# STM32F479 register map
File version: 2.0
CPU: CM4 r0p1, little endian, MPU, FPU, 4 interrupt priority bits
Registers are 32-bit, read-write, reset 0x0 unless marked. A register's access mark holds for its fields unless they carry their own. Offsets are from the block's base; [hi:lo] are bit positions; {n}, {i} and the like mark numbered series.

## HASH — Hash processor
Base 0x50060400
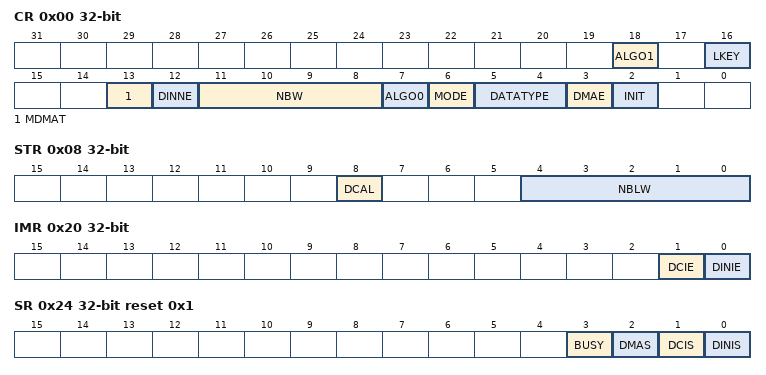
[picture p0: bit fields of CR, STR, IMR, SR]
0x00 CR access per field — control register
  [18] ALGO1 rw — ALGO
  [16] LKEY rw — Long key selection
  [13] MDMAT rw — Multiple DMA Transfers
  [12] DINNE ro — DIN not empty
  [11:8] NBW ro — Number of words already pushed
  [7] ALGO0 rw — Algorithm selection
  [6] MODE rw — Mode selection
  [5:4] DATATYPE rw — Data type selection
  [3] DMAE rw — DMA enable
  [2] INIT wo — Initialize message digest calculation
0x04 DIN — data input register
  [31:0] DATAIN — Data input
0x08 STR access per field — start register
  [8] DCAL wo — Digest calculation
  [4:0] NBLW rw — Number of valid bits in the last word of the message
{0xC+4i} HR{i} ro (i=0..4) — digest registers
  [31:0] H{i}
0x20 IMR — interrupt enable register
  [1] DCIE — Digest calculation completion interrupt enable
  [0] DINIE — Data input interrupt enable
0x24 SR access per field reset 0x1 — status register
  [3] BUSY ro — Busy bit
  [2] DMAS ro — DMA Status
  [1] DCIS rw — Digest calculation completion interrupt status
  [0] DINIS rw — Data input interrupt status
{0xF8+4i} CSR{i} (i=0..53) — context swap registers
0x310 HASH_HR0 ro — HASH digest register
  [31:0] H0
{0x310+4i} HASH_HR{i} ro (i=1..7) — read-only
  [31:0] H{i}

## I2C3 — Inter-integrated circuit
Base 0x40005C00
Same registers: I2C1 0x40005400, I2C2 0x40005800
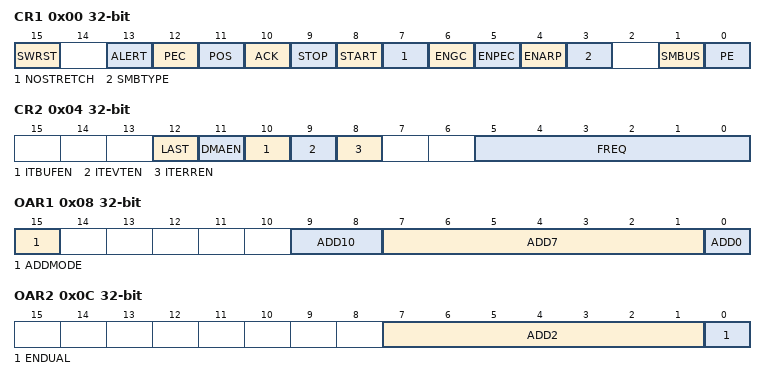
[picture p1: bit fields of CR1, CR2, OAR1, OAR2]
0x00 CR1 — Control register 1
  [15] SWRST — Software reset
  [13] ALERT — SMBus alert
  [12] PEC — Packet error checking
  [11] POS — Acknowledge/PEC Position (for data reception)
  [10] ACK — Acknowledge enable
  [9] STOP — Stop generation
  [8] START — Start generation
  [7] NOSTRETCH — Clock stretching disable (Slave mode)
  [6] ENGC — General call enable
  [5] ENPEC — PEC enable
  [4] ENARP — ARP enable
  [3] SMBTYPE — SMBus type
  [1] SMBUS — SMBus mode
  [0] PE — Peripheral enable
0x04 CR2 — Control register 2
  [12] LAST — DMA last transfer
  [11] DMAEN — DMA requests enable
  [10] ITBUFEN — Buffer interrupt enable
  [9] ITEVTEN — Event interrupt enable
  [8] ITERREN — Error interrupt enable
  [5:0] FREQ — Peripheral clock frequency
0x08 OAR1 — Own address register 1
  [15] ADDMODE — Addressing mode (slave mode)
  [9:8] ADD10 — Interface address
  [7:1] ADD7 — Interface address
  [0] ADD0 — Interface address
0x0C OAR2 — Own address register 2
  [7:1] ADD2 — Interface address
  [0] ENDUAL — Dual addressing mode enable
0x10 DR — Data register
  [7:0] DR — 8-bit data register
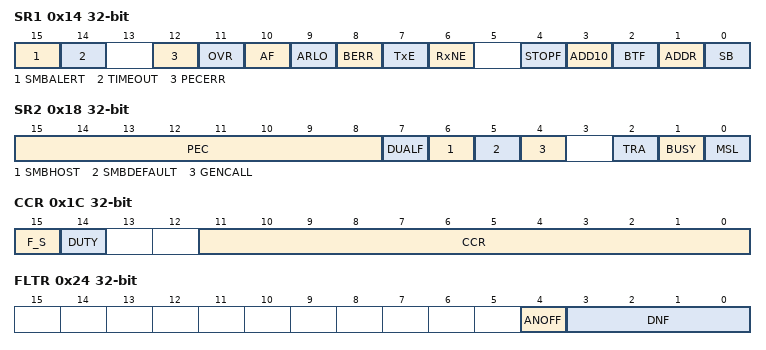
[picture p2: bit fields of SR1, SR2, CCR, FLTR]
0x14 SR1 access per field — Status register 1
  [15] SMBALERT rw — SMBus alert
  [14] TIMEOUT rw — Timeout or Tlow error
  [12] PECERR rw — PEC Error in reception
  [11] OVR rw — Overrun/Underrun
  [10] AF rw — Acknowledge failure
  [9] ARLO rw — Arbitration lost (master mode)
  [8] BERR rw — Bus error
  [7] TxE ro — Data register empty (transmitters)
  [6] RxNE ro — Data register not empty (receivers)
  [4] STOPF ro — Stop detection (slave mode)
  [3] ADD10 ro — 10-bit header sent (Master mode)
  [2] BTF ro — Byte transfer finished
  [1] ADDR ro — Address sent (master mode)/matched (slave mode)
  [0] SB ro — Start bit (Master mode)
0x18 SR2 ro — Status register 2
  [15:8] PEC — acket error checking register
  [7] DUALF — Dual flag (Slave mode)
  [6] SMBHOST — SMBus host header (Slave mode)
  [5] SMBDEFAULT — SMBus device default address (Slave mode)
  [4] GENCALL — General call address (Slave mode)
  [2] TRA — Transmitter/receiver
  [1] BUSY — Bus busy
  [0] MSL — Master/slave
0x1C CCR — Clock control register
  [15] F_S — I2C master mode selection
  [14] DUTY — Fast mode duty cycle
  [11:0] CCR — Clock control register in Fast/Standard mode (Master mode)
0x20 TRISE reset 0x2
  [5:0] TRISE — Maximum rise time in Fast/Standard mode (Master mode)
0x24 FLTR — I2C FLTR register
  [4] ANOFF — Analog noise filter OFF
  [3:0] DNF — Digital noise filter
